# ExynosT100 register map
Vendor: SAMSUNG System LSI; Series: ARMCM4F; File version: 0.1
CPU: CM4 r1p0, little endian, MPU, FPU, 3 interrupt priority bits
Registers are 32-bit, read-write, reset 0x0 unless marked. A register's access mark holds for its fields unless they carry their own. Offsets are from the block's base; [hi:lo] are bit positions; {n}, {i} and the like mark numbered series; 'fields as' and 'values as' point back to an identical list.

## CMU — Clock management
Base 0x40080000
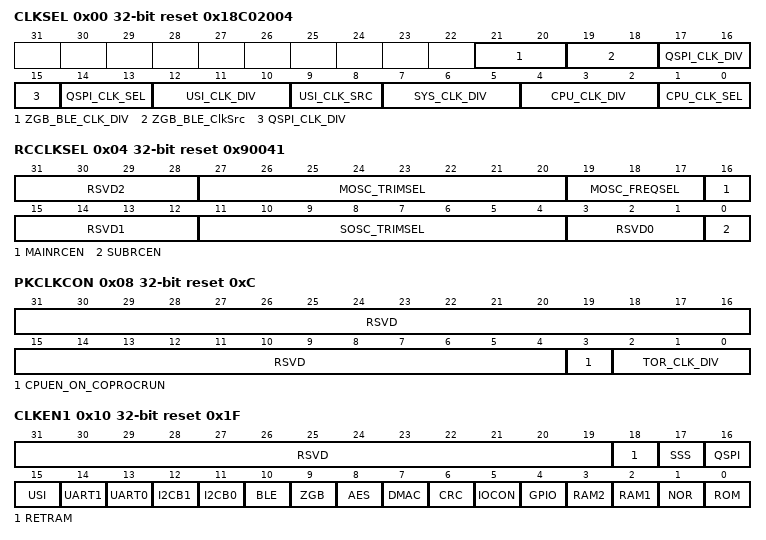
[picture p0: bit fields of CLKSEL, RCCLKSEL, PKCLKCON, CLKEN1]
0x00 CLKSEL reset 0x18C02004 — Clock Selection Register
  [21:20] ZGB_BLE_CLK_DIV — ZGB/BLE clock div 000 = Divided by 1 001 = Divided by 2 010 = Divided by 4 011 = Divided by 6
  [19:18] ZGB_BLE_ClkSrc — ZGB/BLE clock selection 00 = DCXO 32 MHz (Reset value) 01 = RCOSC 64 ~ 100 MHz 11 = Reserved (Default DCXO)
  [17:15] QSPI_CLK_DIV — QSPI master clock 000 = Divided by 1 001 = Divided by 2 010 = Divided by 4 011 = Divided by 6
  [14:13] QSPI_CLK_SEL — QSPI Clock selection 00 = DCXO 32 MHz 01 = RCOSC 64 ~ 100 MHz (Reset value) 11 = Reserved (Default RCOSC)
  [12:10] USI_CLK_DIV — USI clock division select bits 000 = Divided by 1 001 = Divided by 2 010 = Divided by 4 011 = Divided by 6
  [9:8] USI_CLK_SRC — USI clock selection 00 = DCXO 32 MHz (Reset value) 01 = RCOSC 64 ~ 100 MHz NOTE: As for UART, it's recommended to use 00b (DCXO 32 MHz for accurate clock).
  [7:5] SYS_CLK_DIV — Peripheral (up to 50 MHz, derived from CPU clock) clock division select bits (derived from CPU clock) 000 = Divided by 1 001 = Divided by 2 010 = Divided by 4 011 = Divided by 6 100 = Divided by 8
  [4:2] CPU_CLK_DIV — CPU clock division select bits 000 = Divided by 1 001 = Divided by 2 (def.) 010 = Divided by 4 011 = Divided by 6 100 = Divided by 8 After changing SysClkDiv value to be divided by N, insert NOP (N * 6) NOP instructions. (N can be 2, 4, 6, and 8)
  [1:0] CPU_CLK_SEL — CPU (64 MHz ~ 100 MHz) clock selection 00 = RCOSC 64 ~ 100 MHz (Reset value) 01 = DCXO 32 MHz 11 = Reserved (Default RCOSC)
0x04 RCCLKSEL reset 0x90041 — Internal RC Oscillator Clock Selection Register
  [31:28] RSVD2 ro
  [27:20] MOSC_TRIMSEL ro — HF_OSC TRIMSEL value after auto trim
  [19:17] MOSC_FREQSEL — 010 = 100 MHz 011 = 80 MHz 100 ~ 111 = 64 MHz
  [16] MAINRCEN — 0 = Disable 1 = Enable internal main RC oscillator
  [15:12] RSVD1 ro
  [11:4] SOSC_TRIMSEL ro — LF_OSC TRIMSEL value after auto trim
  [3:1] RSVD0 ro
  [0] SUBRCEN — 0 = Disable 1 = Enable internal 2 MHz RC Oscillator
0x08 PKCLKCON reset 0xC — It's Register
  [31:4] RSVD ro, [3] CPUEN_ON_COPROCRUN, [2:0] TOR_CLK_DIV
0x10 CLKEN1 reset 0x1F — Clock Enable 1 Register
  [31:19] RSVD — Must be 0
  [18] RETRAM
  [17] SSS
  [16] QSPI
  [15] USI
  [14] UART1
  [13] UART0
  [12] I2CB1
  [11] I2CB0
  [10] BLE
  [9] ZGB
  [8] AES
  [7] DMAC
  [6] CRC
  [5] IOCON
  [4] GPIO
  [3] RAM2
  [2] RAM1
  [1] NOR
  [0] ROM
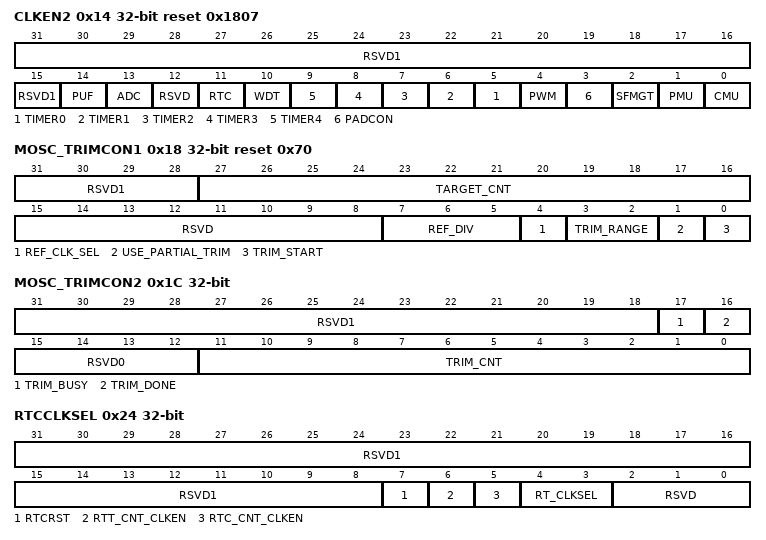
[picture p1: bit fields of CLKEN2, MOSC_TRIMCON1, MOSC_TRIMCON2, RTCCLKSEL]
0x14 CLKEN2 reset 0x1807 — Clock Enable 2 Register
  [31:15] RSVD1 ro — Must be 0
  [14] PUF
  [13] ADC
  [12] RSVD
  [11] RTC
  [10] WDT
  [n+5] TIMER{n} (n=0..4)
  [4] PWM
  [3] PADCON
  [2] SFMGT
  [1] PMU
  [0] CMU
0x18 MOSC_TRIMCON1 reset 0x70 — HF_OSC Trim Control Register 1
  [31:28] RSVD1 ro
  [27:16] TARGET_CNT — Target clock matching count (consider REF_CLK, REF_DIV, target frequency) 100 MHz: 133 (85h) @ 32 MHz with Div128 80 MHz: 107 (6Bh) @ 32 MHz with Div128 64 MHz: 85 (C8h) @ 32 MHz with Div128
  [15:8] RSVD ro
  [7:5] REF_DIV — 000, 101, 110, 111 = Div1 001 = Div32 010 = Div64 011 = Div128 (def.) 100 = Div256
  [4] REF_CLK_SEL — 0 = XI 32.768 kHz 1 = DCXO 32 MHz
  [3:2] TRIM_RANGE — Trim range selection 00 = Trim range FSEL[6:0] 01 = Trim range FSEL[5:0] 10 = Trim range FSEL[4:0] 11 = Trim range FSEL[3:0]
  [1] USE_PARTIAL_TRIM — 0 = Not use trim range (Full TRIM FSEL[7:0]) 1 = Use trim range
  [0] TRIM_START — Start command to trim 100 MHz osc
0x1C MOSC_TRIMCON2 ro — HF_OSC Trim Control Register 2
  [31:18] RSVD1
  [17] TRIM_BUSY — Trim busy flag 0 = Done 1 = Busy
  [16] TRIM_DONE — Trim done flag 0 = Running 1 = Done
  [15:12] RSVD0
  [11:0] TRIM_CNT — Should read after TRIM_BUSY bit is low
0x24 RTCCLKSEL — It's Register
  [31:8] RSVD1 ro
  [7] RTCRST — RTC counter reset enable 0 = Does not reset RTC count 1 = Resets RTC count
  [6] RTT_CNT_CLKEN ro — Must be 0
  [5] RTC_CNT_CLKEN — RTC counter clock enable 0 = Clock disable 1 = Clock enable
  [4:3] RT_CLKSEL
  [2:0] RSVD ro
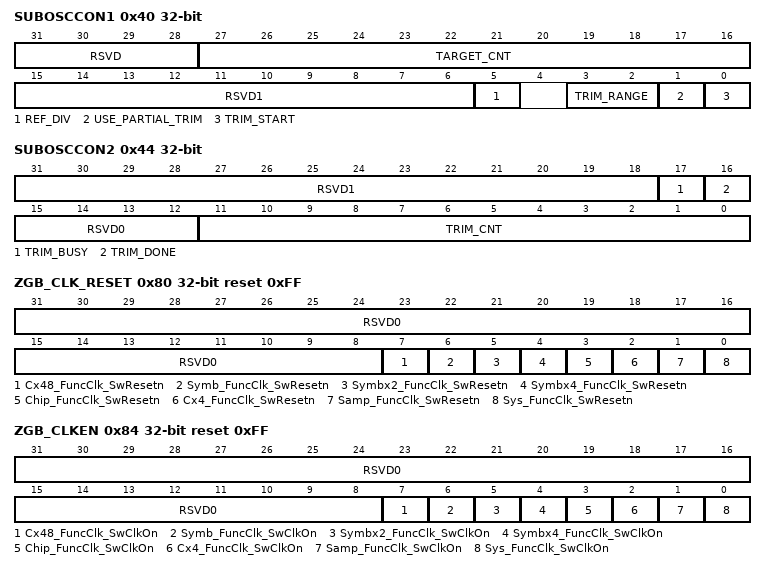
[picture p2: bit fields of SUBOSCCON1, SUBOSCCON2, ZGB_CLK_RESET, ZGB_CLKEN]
0x40 SUBOSCCON1 — LF_OSC Trim Control Register 1
  [31:28] RSVD
  [27:16] TARGET_CNT ro — Target clock matching count (consider REF_CLK, REF_DIV, target frequency) For example, 2 MHz: 32 (20h) @ 32 MHz with Div 512 4 MHz: 64 (40h) @ 32 MHz with Div 512 6 MHz: 96 (60h) @ 32 MHz with Div 512
  [15:6] RSVD1
  [5] REF_DIV — 0 = Div 512 (Ref. clock = 32 MHz/512) 1 = Div 1024 (Ref. clock = 32 MHz/1024)
  [3:2] TRIM_RANGE — Trim range selection 00 = Trim range FSEL[6:0] 01 = Trim range FSEL[5:0] 10 = Trim range FSEL[4:0] 11 = Trim range FSEL[3:0]
  [1] USE_PARTIAL_TRIM — 0 = Not use trim range (Full TRIM FSEL[7:0]) 1 = Use trim range
  [0] TRIM_START — Start command to trim 4 MHz LF_OSC
0x44 SUBOSCCON2 ro — LF_OSC Trim Control Register 2
  fields as MOSC_TRIMCON2
0x80 ZGB_CLK_RESET reset 0xFF — ZGB Clock S/W Reset Register Apply S/W reset to turn on S/W reset for specific clock source, and then turn off S/W reset again 0 = Reset 1 = Write 1 to this bit to clear reset
  [31:8] RSVD0 ro, [7] Cx48_FuncClk_SwResetn, [6] Symb_FuncClk_SwResetn, [5] Symbx2_FuncClk_SwResetn, [4] Symbx4_FuncClk_SwResetn, [3] Chip_FuncClk_SwResetn, [2] Cx4_FuncClk_SwResetn, [1] Samp_FuncClk_SwResetn, [0] Sys_FuncClk_SwResetn
0x84 ZGB_CLKEN reset 0xFF — ZGB Clock Enable Register
  [31:8] RSVD0 ro, [7] Cx48_FuncClk_SwClkOn, [6] Symb_FuncClk_SwClkOn, [5] Symbx2_FuncClk_SwClkOn, [4] Symbx4_FuncClk_SwClkOn, [3] Chip_FuncClk_SwClkOn, [2] Cx4_FuncClk_SwClkOn, [1] Samp_FuncClk_SwClkOn, [0] Sys_FuncClk_SwClkOn
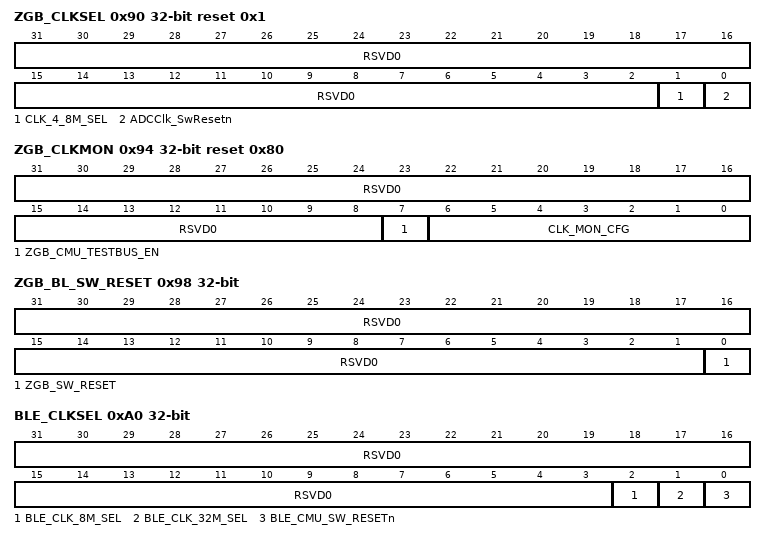
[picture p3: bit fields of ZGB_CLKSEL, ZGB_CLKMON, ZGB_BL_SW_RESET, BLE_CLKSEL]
0x90 ZGB_CLKSEL reset 0x1 — ZGB Clock S/W Reset Register Apply S/W reset to turn on S/W reset for specific clock source, and then turn off S/W reset again 0 = Reset 1 = Write 1 to this bit to clear reset
  [31:2] RSVD0 ro
  [1] CLK_4_8M_SEL — Frequency of o_CLK_ZGB_4M8M 0 = 4 MHz 1 = 8 MHz
  [0] ADCClk_SwResetn — Apply S/W reset turn on S/W reset for specific clock source, and then turn off S/W reset again 0 = Reset 1 = For clear reset, should write 1
0x94 ZGB_CLKMON reset 0x80 — ZGB Clock S/W Reset Register Apply S/W reset to turn on S/W reset for specific clock source, and then turn off S/W reset again 0 = Reset 1 = Write 1 to this bit to clear reset
  [31:8] RSVD0 ro
  [7] ZGB_CMU_TESTBUS_EN — If 0, 32'b stuck 0 If 1, following signals can be monitored: [0] = ClkOn_Sys_Clk [1] = Clkon_Symb_Clk [2] = Clkon_Symbx2_Clk [3] = Clkon_Symbx4_Clk [4] = Clkon_Chip_Clk [5] = Clkon_Cx48_Clk [6] = Clkon_Cx4_Clk [7] = Clkon_Samp_Clk [8] = wDivClkEn_D512 [9] = wDivClkEn_D256 [10] = wDivClkEn_D128 [11] = wDivClkEn_D16 [12] = wDivClkEn_D48 [13] = wDivClkEn_D8 [14] = wDivClkEn_D4 [15] = wDivClkEn_D1 [16] = wClkOvrEn_D2n [19:17] = 0 [20] = i_DivEn [31:21] = 11'b0
  [6:0] CLK_MON_CFG — [0 = Sys_Clk_Gat [1] = Samp_Clk_Gat [2] = Cx4_Clk_Gat [3] = chip_Clk_Gat [4] = Symbx4_Clk_Gat [5] = Symbx2_Clk_Gat [6] = Symb_Clk_Gat [7] = i_SCAN_CLK1 Default = Sys_Clk_Gat
0x98 ZGB_BL_SW_RESET — ZGB Clock S/W Reset Register Apply S/W reset to turn on S/W reset for specific clock source, and then turn off S/W reset again 0 = Reset 1 = Write 1 to this bit to clear reset
  [31:1] RSVD0 ro
  [0] ZGB_SW_RESET — 0 = No reset 1 = Reset all ZGB blocks (Auto clear)
0xA0 BLE_CLKSEL — ZGB Clock S/W Reset Register Apply S/W reset to turn on S/W reset for specific clock source, and then turn off S/W reset again 0 = Reset 1 = Write 1 to this bit to clear reset
  [31:3] RSVD0 ro
  [2] BLE_CLK_8M_SEL — 0 = 4 MHz 1 = 8 MHz
  [1] BLE_CLK_32M_SEL — 0 = 16 MHz/4 MHz 1 = 32 MHz/8 MHz
  [0] BLE_CMU_SW_RESETn — Apply S/W reset turn on S/W reset for specific clock source, and then turn off S/W reset again 0 = No reset 1 = Reset all BLE blocks (auto clear)
